# CC2753 register map
File version: 1.0
CPU: CM0+ r0p4, little endian, no MPU, no FPU, VTOR, 3 interrupt priority bits
Registers are 32-bit, read-write, reset 0x0 unless marked. A register's access mark holds for its fields unless they carry their own. Offsets are from the block's base; [hi:lo] are bit positions; {n}, {i} and the like mark numbered series; 'fields as' and 'values as' point back to an identical list.

## LRFDMDM (part 2 of 2)
Base 0x40082000
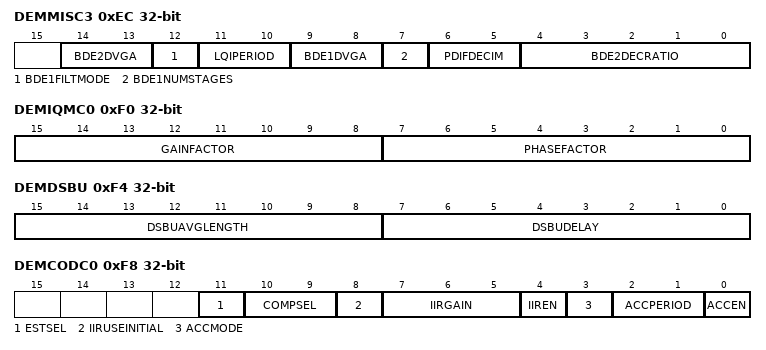
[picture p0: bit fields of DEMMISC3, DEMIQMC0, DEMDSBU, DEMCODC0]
0xEC DEMMISC3 — Internal. Only to be used through TI provided API.
  [14:13] BDE2DVGA — Internal. Only to be used through TI provided API.
    3=GAIN8 (Internal. Only to be used through TI provided API.); 2=GAIN4 (Internal. Only to be used through TI provided API.); 1=GAIN2 (Internal. Only to be used through TI provided API.); 0=GAIN1 (Internal. Only to be used through TI provided API.)
  [12] BDE1FILTMODE — Internal. Only to be used through TI provided API.
    1=DIV2 (Internal. Only to be used through TI provided API.); 0=DIV1 (Internal. Only to be used through TI provided API.)
  [11:10] LQIPERIOD — Internal. Only to be used through TI provided API.
    3=SYM1024 (Internal. Only to be used through TI provided API.); 2=SYM256 (Internal. Only to be used through TI provided API.); 1=SYM64 (Internal. Only to be used through TI provided API.); 0=SYM16 (Internal. Only to be used through TI provided API.)
  [9:8] BDE1DVGA — Internal. Only to be used through TI provided API.
    values as BDE2DVGA
  [7] BDE1NUMSTAGES — Internal. Only to be used through TI provided API.
    values as BDE1FILTMODE
  [6:5] PDIFDECIM — Internal. Only to be used through TI provided API.
    2=DIV4 (Internal. Only to be used through TI provided API.); 1=DIV2 (Internal. Only to be used through TI provided API.); 0=DIV1 (Internal. Only to be used through TI provided API.)
  [4:0] BDE2DECRATIO — Internal. Only to be used through TI provided API.
    3=DIV8 (Internal. Only to be used through TI provided API.); 2=DIV4 (Internal. Only to be used through TI provided API.); 1=DIV2 (Internal. Only to be used through TI provided API.); 0=DIV1 (Internal. Only to be used through TI provided API.)
0xF0 DEMIQMC0 — Internal. Only to be used through TI provided API.
  [15:8] GAINFACTOR — Internal. Only to be used through TI provided API.
    255=ALLONES (Internal. Only to be used through TI provided API.); 0=ALLZEROS (Internal. Only to be used through TI provided API.)
  [7:0] PHASEFACTOR — Internal. Only to be used through TI provided API.
    values as GAINFACTOR
0xF4 DEMDSBU — Internal. Only to be used through TI provided API.
  [15:8] DSBUAVGLENGTH — Internal. Only to be used through TI provided API.
    values as DEMIQMC0.GAINFACTOR
  [7:0] DSBUDELAY — Internal. Only to be used through TI provided API.
    values as DEMIQMC0.GAINFACTOR
0xF8 DEMCODC0 — Internal. Only to be used through TI provided API.
  [11] ESTSEL — Internal. Only to be used through TI provided API.
    1=IIR (Internal. Only to be used through TI provided API.); 0=ACC (Internal. Only to be used through TI provided API.)
  [10:9] COMPSEL — Internal. Only to be used through TI provided API.
    3=IIR (Internal. Only to be used through TI provided API.); 2=ACC (Internal. Only to be used through TI provided API.); 0=MANUAL (Internal. Only to be used through TI provided API.)
  [8] IIRUSEINITIAL — Internal. Only to be used through TI provided API.
    1=EN (Internal. Only to be used through TI provided API.); 0=DIS (Internal. Only to be used through TI provided API.)
  [7:5] IIRGAIN — Internal. Only to be used through TI provided API.
    7=DIV1024 (Internal. Only to be used through TI provided API.); 6=DIV512 (Internal. Only to be used through TI provided API.); 5=DIV256 (Internal. Only to be used through TI provided API.); 4=DIV128 (Internal. Only to be used through TI provided API.); 3=DIV64 (Internal. Only to be used through TI provided API.); 2=DIV32 (Internal. Only to be used through TI provided API.); 1=DIV16 (Internal. Only to be used through TI provided API.); 0=OFF (Internal. Only to be used through TI provided API.)
  [4] IIREN — Internal. Only to be used through TI provided API.
    1=ON (Internal. Only to be used through TI provided API.); 0=OFF (Internal. Only to be used through TI provided API.)
  [3] ACCMODE — Internal. Only to be used through TI provided API.
    1=CONT (Internal. Only to be used through TI provided API.); 0=SINGLE (Internal. Only to be used through TI provided API.)
  [2:1] ACCPERIOD — Internal. Only to be used through TI provided API.
    3=SMPL512 (Internal. Only to be used through TI provided API.); 2=SMPL128 (Internal. Only to be used through TI provided API.); 1=SMPL32 (Internal. Only to be used through TI provided API.); 0=SMPL8 (Internal. Only to be used through TI provided API.)
  [0] ACCEN — Internal. Only to be used through TI provided API.
    values as IIREN
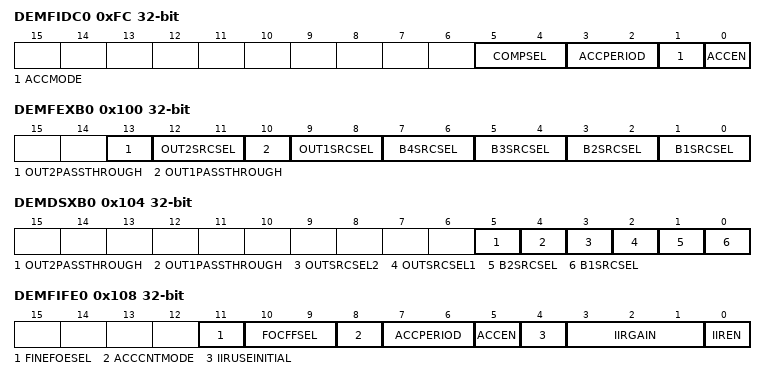
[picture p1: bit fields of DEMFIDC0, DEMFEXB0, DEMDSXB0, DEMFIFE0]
0xFC DEMFIDC0 — Internal. Only to be used through TI provided API.
  [5:4] COMPSEL — Internal. Only to be used through TI provided API.
    2=ACC (Internal. Only to be used through TI provided API.); 0=MANUAL (Internal. Only to be used through TI provided API.)
  [3:2] ACCPERIOD — Internal. Only to be used through TI provided API.
    values as DEMCODC0.ACCPERIOD
  [1] ACCMODE — Internal. Only to be used through TI provided API.
    values as DEMCODC0.ACCMODE
  [0] ACCEN — Internal. Only to be used through TI provided API.
    values as DEMCODC0.IIREN
0x100 DEMFEXB0 — Internal. Only to be used through TI provided API.
  [13] OUT2PASSTHROUGH — Internal. Only to be used through TI provided API.
    1=ONE (Internal. Only to be used through TI provided API.); 0=ZERO (Internal. Only to be used through TI provided API.)
  [12:11] OUT2SRCSEL — Internal. Only to be used through TI provided API.
    2=BDE1 (Internal. Only to be used through TI provided API.); 1=CMIX (Internal. Only to be used through TI provided API.); 0=CODC (Internal. Only to be used through TI provided API.)
  [10] OUT1PASSTHROUGH — Internal. Only to be used through TI provided API.
    values as OUT2PASSTHROUGH
  [9:8] OUT1SRCSEL — Internal. Only to be used through TI provided API.
    values as OUT2SRCSEL
  [7:6] B4SRCSEL — Internal. Only to be used through TI provided API.
    3=ONES (Internal. Only to be used through TI provided API.); 0=ZEROS (Internal. Only to be used through TI provided API.)
  [5:4] B3SRCSEL — Internal. Only to be used through TI provided API.
    2=CMIX (Internal. Only to be used through TI provided API.); 1=CODC (Internal. Only to be used through TI provided API.); 0=INPUT (Internal. Only to be used through TI provided API.)
  [3:2] B2SRCSEL — Internal. Only to be used through TI provided API.
    2=BDE1 (Internal. Only to be used through TI provided API.); 1=CODC (Internal. Only to be used through TI provided API.); 0=INPUT (Internal. Only to be used through TI provided API.)
  [1:0] B1SRCSEL — Internal. Only to be used through TI provided API.
    2=BDE1 (Internal. Only to be used through TI provided API.); 1=CMIX (Internal. Only to be used through TI provided API.); 0=INPUT (Internal. Only to be used through TI provided API.)
0x104 DEMDSXB0 — Internal. Only to be used through TI provided API.
  [5] OUT2PASSTHROUGH — Internal. Only to be used through TI provided API.
    values as DEMFEXB0.OUT2PASSTHROUGH
  [4] OUT1PASSTHROUGH — Internal. Only to be used through TI provided API.
    values as DEMFEXB0.OUT2PASSTHROUGH
  [3] OUTSRCSEL2 — Internal. Only to be used through TI provided API.
    1=MAFI (Internal. Only to be used through TI provided API.); 0=FIFE (Internal. Only to be used through TI provided API.)
  [2] OUTSRCSEL1 — Internal. Only to be used through TI provided API.
    values as OUTSRCSEL2
  [1] B2SRCSEL — Internal. Only to be used through TI provided API.
    1=FIFE (Internal. Only to be used through TI provided API.); 0=INPUT (Internal. Only to be used through TI provided API.)
  [0] B1SRCSEL — Internal. Only to be used through TI provided API.
    1=MAFI (Internal. Only to be used through TI provided API.); 0=INPUT (Internal. Only to be used through TI provided API.)
0x108 DEMFIFE0 — Internal. Only to be used through TI provided API.
  [11] FINEFOESEL — Internal. Only to be used through TI provided API.
    1=ACC (Internal. Only to be used through TI provided API.); 0=IIR (Internal. Only to be used through TI provided API.)
  [10:9] FOCFFSEL — Internal. Only to be used through TI provided API.
    2=MANUAL (Internal. Only to be used through TI provided API.); 1=ACC (Internal. Only to be used through TI provided API.); 0=IIR (Internal. Only to be used through TI provided API.)
  [8] ACCCNTMODE — Internal. Only to be used through TI provided API.
    values as DEMCODC0.ACCMODE
  [7:6] ACCPERIOD — Internal. Only to be used through TI provided API.
    3=PER512 (Internal. Only to be used through TI provided API.); 2=PER256 (Internal. Only to be used through TI provided API.); 1=PER128 (Internal. Only to be used through TI provided API.); 0=PER64 (Internal. Only to be used through TI provided API.)
  [5] ACCEN — Internal. Only to be used through TI provided API.
    values as DEMCODC0.IIREN
  [4] IIRUSEINITIAL — Internal. Only to be used through TI provided API.
    values as DEMCODC0.IIRUSEINITIAL
  [3:1] IIRGAIN — Internal. Only to be used through TI provided API.
    values as DEMCODC0.IIRGAIN
  [0] IIREN — Internal. Only to be used through TI provided API.
    values as DEMCODC0.IIREN
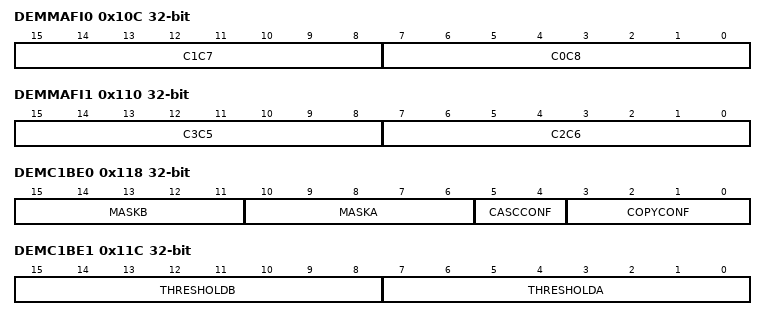
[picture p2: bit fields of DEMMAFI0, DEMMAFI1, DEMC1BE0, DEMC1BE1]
0x10C DEMMAFI0 — Internal. Only to be used through TI provided API.
  [15:8] C1C7 — Internal. Only to be used through TI provided API.
    values as DEMIQMC0.GAINFACTOR
  [7:0] C0C8 — Internal. Only to be used through TI provided API.
    values as DEMIQMC0.GAINFACTOR
0x110 DEMMAFI1 — Internal. Only to be used through TI provided API.
  [15:8] C3C5 — Internal. Only to be used through TI provided API.
    values as DEMIQMC0.GAINFACTOR
  [7:0] C2C6 — Internal. Only to be used through TI provided API.
    values as DEMIQMC0.GAINFACTOR
0x114 DEMMAFI2 — Internal. Only to be used through TI provided API.
  [8:0] C4
    0x1FF=ALLONES (Internal. Only to be used through TI provided API.); 0=ALLZEROS (Internal. Only to be used through TI provided API.)
0x118 DEMC1BE0 — Internal. Only to be used through TI provided API.
  [15:11] MASKB — Internal. Only to be used through TI provided API.
    31=ALLONES (Internal. Only to be used through TI provided API.); 0=ALLZEROS (Internal. Only to be used through TI provided API.)
  [10:6] MASKA — Internal. Only to be used through TI provided API.
    values as MASKB
  [5:4] CASCCONF — Internal. Only to be used through TI provided API.
    2=PARALLEL (Internal. Only to be used through TI provided API.); 1=SERIAL (Internal. Only to be used through TI provided API.); 0=SINGLE (Internal. Only to be used through TI provided API.)
  [3:0] COPYCONF — Internal. Only to be used through TI provided API.
    15=ALLONES (Internal. Only to be used through TI provided API.); 0=ALLZEROS (Internal. Only to be used through TI provided API.)
0x11C DEMC1BE1 — Internal. Only to be used through TI provided API.
  [15:8] THRESHOLDB — Internal. Only to be used through TI provided API.
    values as DEMIQMC0.GAINFACTOR
  [7:0] THRESHOLDA — Internal. Only to be used through TI provided API.
    values as DEMIQMC0.GAINFACTOR
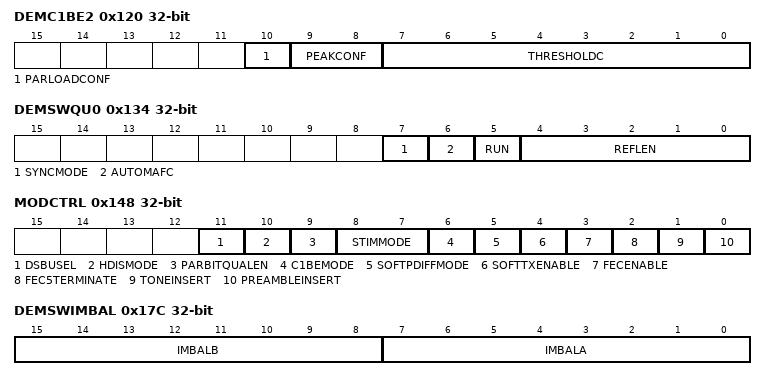
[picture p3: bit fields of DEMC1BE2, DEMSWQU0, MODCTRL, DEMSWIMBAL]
0x120 DEMC1BE2 — Internal. Only to be used through TI provided API.
  [10] PARLOADCONF — Internal. Only to be used through TI provided API.
    1=ATOD (Internal. Only to be used through TI provided API.); 0=ATOB (Internal. Only to be used through TI provided API.)
  [9:8] PEAKCONF — Internal. Only to be used through TI provided API.
    2=BESTAB (Internal. Only to be used through TI provided API.); 1=BEST (Internal. Only to be used through TI provided API.); 0=THRESH (Internal. Only to be used through TI provided API.)
  [7:0] THRESHOLDC — Internal. Only to be used through TI provided API.
    values as DEMIQMC0.GAINFACTOR
{0x124+4i} SPARE{i} (i=0..3) — Internal. Only to be used through TI provided API.
  [15:0] VAL
    0xFFFF=ALLONES (Internal. Only to be used through TI provided API.); 0=ALLZEROS (Internal. Only to be used through TI provided API.)
0x134 DEMSWQU0 — Internal. Only to be used through TI provided API.
  [7] SYNCMODE — Internal. Only to be used through TI provided API.
    values as DEMFEXB0.OUT2PASSTHROUGH
  [6] AUTOMAFC — Internal. Only to be used through TI provided API.
    values as DEMCODC0.IIREN
  [5] RUN — Internal. Only to be used through TI provided API.
    values as DEMCODC0.IIREN
  [4:0] REFLEN — Internal. Only to be used through TI provided API.
    values as DEMC1BE0.MASKB
0x138 DEMC1BEREF0 — Internal. Only to be used through TI provided API.
  [15:0] CAR15C0
    values as SPARE0.VAL
0x13C DEMC1BEREF1 — Internal. Only to be used through TI provided API.
  [15:0] CAR31C16
    values as SPARE0.VAL
0x140 DEMC1BEREF2 — Internal. Only to be used through TI provided API.
  [15:0] CBR15C0
    values as SPARE0.VAL
0x144 DEMC1BEREF3 — Internal. Only to be used through TI provided API.
  [15:0] CBR31C16
    values as SPARE0.VAL
0x148 MODCTRL — Internal. Only to be used through TI provided API.
  [11] DSBUSEL — Internal. Only to be used through TI provided API.
    values as DEMFEXB0.OUT2PASSTHROUGH
  [10] HDISMODE — Internal. Only to be used through TI provided API.
    values as DEMCODC0.IIRUSEINITIAL
  [9] PARBITQUALEN — Internal. Only to be used through TI provided API.
    values as DEMCODC0.IIREN
  [8:7] STIMMODE — Internal. Only to be used through TI provided API.
    2=EARLY (Internal. Only to be used through TI provided API.); 1=LATE (Internal. Only to be used through TI provided API.); 0=NORMAL (Internal. Only to be used through TI provided API.)
  [6] C1BEMODE — Internal. Only to be used through TI provided API.
    1=EARLYLATE (Internal. Only to be used through TI provided API.); 0=NORMAL (Internal. Only to be used through TI provided API.)
  [5] SOFTPDIFFMODE — Internal. Only to be used through TI provided API.
    values as DEMCODC0.IIRUSEINITIAL
  [4] SOFTTXENABLE — Internal. Only to be used through TI provided API.
    values as DEMCODC0.IIREN
  [3] FECENABLE — Internal. Only to be used through TI provided API.
    values as DEMCODC0.IIREN
  [2] FEC5TERMINATE — Internal. Only to be used through TI provided API.
    values as DEMCODC0.IIREN
  [1] TONEINSERT — Internal. Only to be used through TI provided API.
    values as DEMCODC0.IIRUSEINITIAL
  [0] PREAMBLEINSERT — Internal. Only to be used through TI provided API.
    values as DEMCODC0.IIRUSEINITIAL
0x14C MODPREAMBLE — Internal. Only to be used through TI provided API.
  [15:0] WORD
    values as SPARE0.VAL
0x150 DEMFRAC0 — Internal. Only to be used through TI provided API.
  [15:0] P15C0
    values as SPARE0.VAL
0x154 DEMFRAC1 — Internal. Only to be used through TI provided API.
  [11:0] P27C16
    0xFFF=ALLONES (Internal. Only to be used through TI provided API.); 0=ALLZEROS (Internal. Only to be used through TI provided API.)
0x158 DEMFRAC2 — Internal. Only to be used through TI provided API.
  [15:0] Q15C0
    values as SPARE0.VAL
0x15C DEMFRAC3 — Internal. Only to be used through TI provided API.
  [11:0] Q27C16
    values as DEMFRAC1.P27C16
0x160 DEMCODC1 — Internal. Only to be used through TI provided API.
  [12:0] COMPIVAL
    0x1FFF=ALLONES (Internal. Only to be used through TI provided API.); 0=ALLZEROS (Internal. Only to be used through TI provided API.)
0x164 DEMCODC2 — Internal. Only to be used through TI provided API.
  [12:0] COMPQVAL
    values as DEMCODC1.COMPIVAL
0x168 DEMFIDC1 — Internal. Only to be used through TI provided API.
  fields as DEMCODC1
0x16C DEMFIDC2 — Internal. Only to be used through TI provided API.
  fields as DEMCODC2
0x170 DEMFIFE1 — Internal. Only to be used through TI provided API.
  [7:0] FOCFBREGVAL
    values as DEMIQMC0.GAINFACTOR
0x174 DEMMAFC0 — Internal. Only to be used through TI provided API.
  [7:0] COMPVAL
    values as DEMIQMC0.GAINFACTOR
0x178 DEMMAFI4 — Internal. Only to be used through TI provided API.
  [7:0] TERMVAL
    values as DEMIQMC0.GAINFACTOR
0x17C DEMSWIMBAL — Internal. Only to be used through TI provided API.
  [15:8] IMBALB — Internal. Only to be used through TI provided API.
    values as DEMIQMC0.GAINFACTOR
  [7:0] IMBALA — Internal. Only to be used through TI provided API.
    values as DEMIQMC0.GAINFACTOR
0x180 DEMSOFTPDIFF — Internal. Only to be used through TI provided API.
  [7:0] VAL
    values as DEMIQMC0.GAINFACTOR
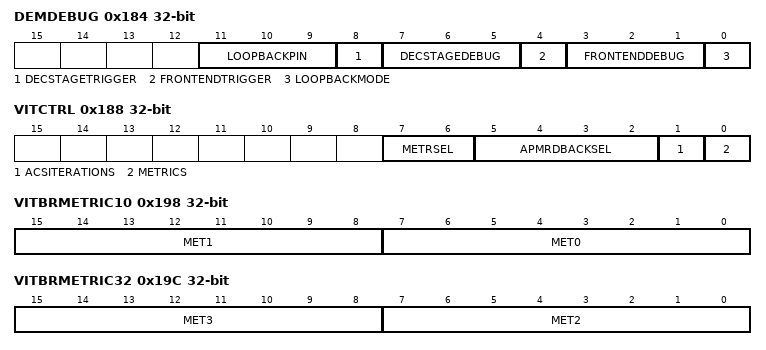
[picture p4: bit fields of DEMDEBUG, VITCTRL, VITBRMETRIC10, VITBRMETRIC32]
0x184 DEMDEBUG — Internal. Only to be used through TI provided API.
  [11:9] LOOPBACKPIN — Internal. Only to be used through TI provided API.
    {v}=GPI{v} (Internal. Only to be used through TI provided API.) (v=0..7)
  [8] DECSTAGETRIGGER — Internal. Only to be used through TI provided API.
    values as DEMFEXB0.OUT2PASSTHROUGH
  [7:5] DECSTAGEDEBUG — Internal. Only to be used through TI provided API.
    7=SOFD (Internal. Only to be used through TI provided API.); 6=STIM (Internal. Only to be used through TI provided API.); 5=MAFC (Internal. Only to be used through TI provided API.); 4=C1BE (Internal. Only to be used through TI provided API.); 3=MAFI (Internal. Only to be used through TI provided API.); 2=FIFE (Internal. Only to be used through TI provided API.); 1=PDIF (Internal. Only to be used through TI provided API.); 0=NOSEL (Internal. Only to be used through TI provided API.)
  [4] FRONTENDTRIGGER — Internal. Only to be used through TI provided API.
    values as DEMFEXB0.OUT2PASSTHROUGH
  [3:1] FRONTENDDEBUG — Internal. Only to be used through TI provided API.
    7=FIDC (Internal. Only to be used through TI provided API.); 6=FRAC (Internal. Only to be used through TI provided API.); 5=CHFI (Internal. Only to be used through TI provided API.); 4=BDE2 (Internal. Only to be used through TI provided API.); 3=FEXB2 (Internal. Only to be used through TI provided API.); 2=BDE1 (Internal. Only to be used through TI provided API.); 1=IQMC (Internal. Only to be used through TI provided API.); 0=NOSEL (Internal. Only to be used through TI provided API.)
  [0] LOOPBACKMODE — Internal. Only to be used through TI provided API.
    values as DEMFEXB0.OUT2PASSTHROUGH
0x188 VITCTRL — Internal. Only to be used through TI provided API.
  [7:6] METRSEL — Internal. Only to be used through TI provided API.
    3=MLSE (Internal. Only to be used through TI provided API.); 2=SOFD (Internal. Only to be used through TI provided API.); 1=PHAC (Internal. Only to be used through TI provided API.); 0=MET5M (Internal. Only to be used through TI provided API.)
  [5:2] APMRDBACKSEL — Internal. Only to be used through TI provided API.
    {v}=APM{v-8} (Internal. Only to be used through TI provided API.) (v=8..15); 0=NOSEL (Internal. Only to be used through TI provided API.)
  [1] ACSITERATIONS — Internal. Only to be used through TI provided API.
    1=CODE23 (Internal. Only to be used through TI provided API.); 0=CODE12 (Internal. Only to be used through TI provided API.)
  [0] METRICS — Internal. Only to be used through TI provided API.
    1=SOFT (Internal. Only to be used through TI provided API.); 0=HW (Internal. Only to be used through TI provided API.)
0x18C VITCOMPUTE wo — Internal. Only to be used through TI provided API.
  [0] START
    values as DEMFEXB0.OUT2PASSTHROUGH
0x190 VITAPMRDBACK ro — Internal. Only to be used through TI provided API.
  [9:0] VALUE
    0x3FF=ALLONES (Internal. Only to be used through TI provided API.); 0=ALLZEROS (Internal. Only to be used through TI provided API.)
0x194 VITSTATE ro — Internal. Only to be used through TI provided API.
  [2:0] VALUE
    7=ALLONES (Internal. Only to be used through TI provided API.); 0=ALLZEROS (Internal. Only to be used through TI provided API.)
0x198 VITBRMETRIC10 — Internal. Only to be used through TI provided API.
  [15:8] MET1 — Internal. Only to be used through TI provided API.
    values as DEMIQMC0.GAINFACTOR
  [7:0] MET0 — Internal. Only to be used through TI provided API.
    values as DEMIQMC0.GAINFACTOR
0x19C VITBRMETRIC32 — Internal. Only to be used through TI provided API.
  [15:8] MET3 — Internal. Only to be used through TI provided API.
    values as DEMIQMC0.GAINFACTOR
  [7:0] MET2 — Internal. Only to be used through TI provided API.
    values as DEMIQMC0.GAINFACTOR
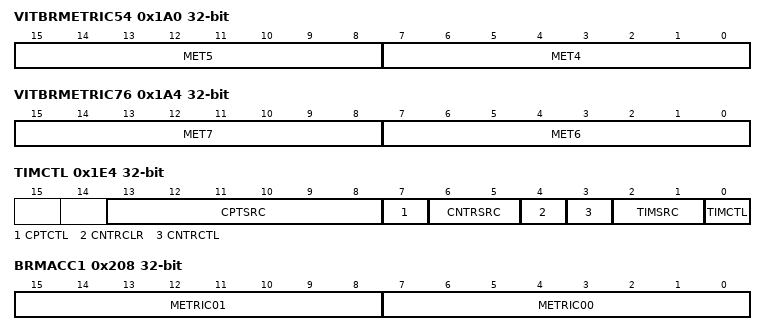
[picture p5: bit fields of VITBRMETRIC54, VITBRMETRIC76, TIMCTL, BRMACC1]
0x1A0 VITBRMETRIC54 — Internal. Only to be used through TI provided API.
  [15:8] MET5 — Internal. Only to be used through TI provided API.
    values as DEMIQMC0.GAINFACTOR
  [7:0] MET4 — Internal. Only to be used through TI provided API.
    values as DEMIQMC0.GAINFACTOR
0x1A4 VITBRMETRIC76 — Internal. Only to be used through TI provided API.
  [15:8] MET7 — Internal. Only to be used through TI provided API.
    values as DEMIQMC0.GAINFACTOR
  [7:0] MET6 — Internal. Only to be used through TI provided API.
    values as DEMIQMC0.GAINFACTOR
0x1E4 TIMCTL — Internal. Only to be used through TI provided API.
  [13:8] CPTSRC — Internal. Only to be used through TI provided API.
    63=ALLONES (Internal. Only to be used through TI provided API.); 0=ALLZEROS (Internal. Only to be used through TI provided API.)
  [7] CPTCTL — Internal. Only to be used through TI provided API.
    values as DEMCODC0.IIRUSEINITIAL
  [6:5] CNTRSRC — Internal. Only to be used through TI provided API.
    3=CLK4BAUDF (Internal. Only to be used through TI provided API.); 2=CLK4BAUD (Internal. Only to be used through TI provided API.); 1=CLKBAUD (Internal. Only to be used through TI provided API.); 0=CLK (Internal. Only to be used through TI provided API.)
  [4] CNTRCLR — Internal. Only to be used through TI provided API.
    values as DEMFEXB0.OUT2PASSTHROUGH
  [3] CNTRCTL — Internal. Only to be used through TI provided API.
    values as DEMFEXB0.OUT2PASSTHROUGH
  [2:1] TIMSRC — Internal. Only to be used through TI provided API.
    values as CNTRSRC
  [0] TIMCTL — Internal. Only to be used through TI provided API.
    values as DEMCODC0.IIRUSEINITIAL
0x1E8 TIMINC — Internal. Only to be used through TI provided API.
  fields as SPARE0
0x1EC TIMPER — Internal. Only to be used through TI provided API.
  fields as SPARE0
0x1F0 TIMCNT ro — Internal. Only to be used through TI provided API.
  fields as SPARE0
0x1F4 TIMCAPT ro — Internal. Only to be used through TI provided API.
  [15:0] VALUE
    values as SPARE0.VAL
0x1F8 TIMEBASE wo — Internal. Only to be used through TI provided API.
  [0] FLUSH
    values as DEMFEXB0.OUT2PASSTHROUGH
0x1FC COUNT1IN — Internal. Only to be used through TI provided API.
  fields as SPARE0
0x200 COUNT1RES ro — Internal. Only to be used through TI provided API.
  [4:0] VAL
    values as DEMC1BE0.MASKB
0x208 BRMACC1 ro — Internal. Only to be used through TI provided API.
  [15:8] METRIC01 — Internal. Only to be used through TI provided API.
    values as DEMIQMC0.GAINFACTOR
  [7:0] METRIC00 — Internal. Only to be used through TI provided API.
    values as DEMIQMC0.GAINFACTOR
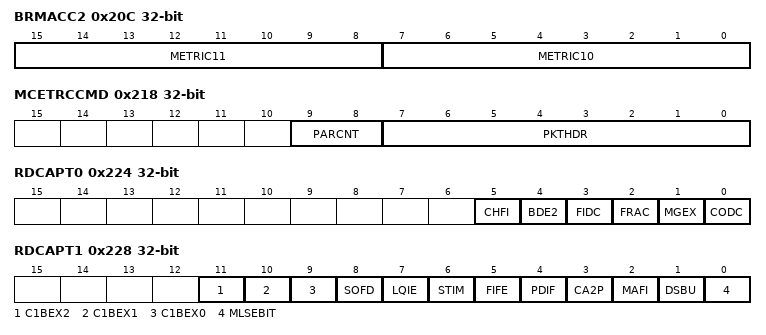
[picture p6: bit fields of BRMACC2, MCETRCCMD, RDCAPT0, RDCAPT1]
0x20C BRMACC2 ro — Internal. Only to be used through TI provided API.
  [15:8] METRIC11 — Internal. Only to be used through TI provided API.
    values as DEMIQMC0.GAINFACTOR
  [7:0] METRIC10 — Internal. Only to be used through TI provided API.
    values as DEMIQMC0.GAINFACTOR
0x210 MCETRCCTRL wo — Internal. Only to be used through TI provided API.
  [0] SEND
    values as DEMFEXB0.OUT2PASSTHROUGH
0x214 MCETRCSTAT ro — Internal. Only to be used through TI provided API.
  [0] BUSY
    values as DEMFEXB0.OUT2PASSTHROUGH
0x218 MCETRCCMD — Internal. Only to be used through TI provided API.
  [9:8] PARCNT — Internal. Only to be used through TI provided API.
    3=ALLONES (Internal. Only to be used through TI provided API.); 0=ALLZEROS (Internal. Only to be used through TI provided API.)
  [7:0] PKTHDR — Internal. Only to be used through TI provided API.
    values as DEMIQMC0.GAINFACTOR
0x21C MCETRCPAR0 — Internal. Only to be used through TI provided API.
  fields as SPARE0
0x220 MCETRCPAR1 — Internal. Only to be used through TI provided API.
  fields as SPARE0
0x224 RDCAPT0 wo — Internal. Only to be used through TI provided API.
  [all] fields
    values as DEMFEXB0.OUT2PASSTHROUGH
  [5] CHFI — Internal. Only to be used through TI provided API.
  [4] BDE2 — Internal. Only to be used through TI provided API.
  [3] FIDC — Internal. Only to be used through TI provided API.
  [2] FRAC — Internal. Only to be used through TI provided API.
  [1] MGEX — Internal. Only to be used through TI provided API.
  [0] CODC — Internal. Only to be used through TI provided API.
0x228 RDCAPT1 wo — Internal. Only to be used through TI provided API.
  [all] fields
    values as DEMFEXB0.OUT2PASSTHROUGH
  [11] C1BEX2 — Internal. Only to be used through TI provided API.
  [10] C1BEX1 — Internal. Only to be used through TI provided API.
  [9] C1BEX0 — Internal. Only to be used through TI provided API.
  [8] SOFD — Internal. Only to be used through TI provided API.
  [7] LQIE — Internal. Only to be used through TI provided API.
  [6] STIM — Internal. Only to be used through TI provided API.
  [5] FIFE — Internal. Only to be used through TI provided API.
  [4] PDIF — Internal. Only to be used through TI provided API.
  [3] CA2P — Internal. Only to be used through TI provided API.
  [2] MAFI — Internal. Only to be used through TI provided API.
  [1] DSBU — Internal. Only to be used through TI provided API.
  [0] MLSEBIT — Internal. Only to be used through TI provided API.
0x22C FECAPT0 — Internal. Only to be used through TI provided API.
  [12:0] VAL
    values as DEMCODC1.COMPIVAL
0x230 FECAPT1 — Internal. Only to be used through TI provided API.
  fields as FECAPT0
{0x234+4i} DSCAPT{i} (i=0..3) — Internal. Only to be used through TI provided API.
  fields as DEMSOFTPDIFF
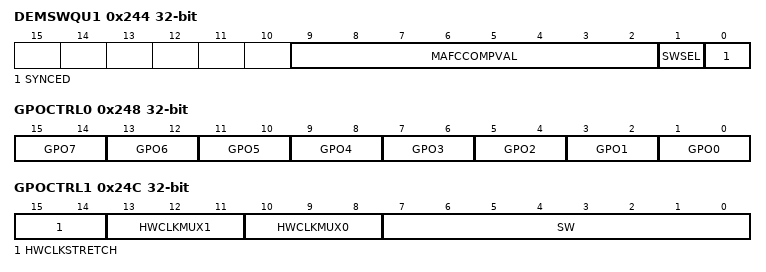
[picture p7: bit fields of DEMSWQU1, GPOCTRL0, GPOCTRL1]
0x244 DEMSWQU1 — Internal. Only to be used through TI provided API.
  [9:2] MAFCCOMPVAL ro — Internal. Only to be used through TI provided API.
    values as DEMIQMC0.GAINFACTOR
  [1] SWSEL ro — Internal. Only to be used through TI provided API.
    1=B (Internal. Only to be used through TI provided API.); 0=A (Internal. Only to be used through TI provided API.)
  [0] SYNCED ro — Internal. Only to be used through TI provided API.
    values as DEMFEXB0.OUT2PASSTHROUGH
0x248 GPOCTRL0 — Internal. Only to be used through TI provided API.
  [15:14] GPO7 — Internal. Only to be used through TI provided API.
    3=THREE (Internal. Only to be used through TI provided API.); 2=TWO (Internal. Only to be used through TI provided API.); 1=TOPSM_WAIT (Internal. Only to be used through TI provided API.); 0=SW7 (Internal. Only to be used through TI provided API.)
  [13:12] GPO6 — Internal. Only to be used through TI provided API.
    3=THREE (Internal. Only to be used through TI provided API.); 2=TWO (Internal. Only to be used through TI provided API.); 1=TRANSPARENT_OUT (Internal. Only to be used through TI provided API.); 0=SW6 (Internal. Only to be used through TI provided API.)
  [11:10] GPO5 — Internal. Only to be used through TI provided API.
    3=THREE (Internal. Only to be used through TI provided API.); 2=TWO (Internal. Only to be used through TI provided API.); 1=DEM_OUT_WORD (Internal. Only to be used through TI provided API.); 0=SW5 (Internal. Only to be used through TI provided API.)
  [9:8] GPO4 — Internal. Only to be used through TI provided API.
    3=THREE (Internal. Only to be used through TI provided API.); 2=TWO (Internal. Only to be used through TI provided API.); 1=CORR_PEAK_C (Internal. Only to be used through TI provided API.); 0=SW4 (Internal. Only to be used through TI provided API.)
  [7:6] GPO3 — Internal. Only to be used through TI provided API.
    3=THREE (Internal. Only to be used through TI provided API.); 2=TWO (Internal. Only to be used through TI provided API.); 1=CORR_PEAK_B (Internal. Only to be used through TI provided API.); 0=SW3 (Internal. Only to be used through TI provided API.)
  [5:4] GPO2 — Internal. Only to be used through TI provided API.
    3=THREE (Internal. Only to be used through TI provided API.); 2=TWO (Internal. Only to be used through TI provided API.); 1=CORR_PEAK_A (Internal. Only to be used through TI provided API.); 0=SW2 (Internal. Only to be used through TI provided API.)
  [3:2] GPO1 — Internal. Only to be used through TI provided API.
    3=THREE (Internal. Only to be used through TI provided API.); 2=TWO (Internal. Only to be used through TI provided API.); 1=HWCLK1 (Internal. Only to be used through TI provided API.); 0=SW1 (Internal. Only to be used through TI provided API.)
  [1:0] GPO0 — Internal. Only to be used through TI provided API.
    3=THREE (Internal. Only to be used through TI provided API.); 2=LOOPBACK (Internal. Only to be used through TI provided API.); 1=HWCLK0 (Internal. Only to be used through TI provided API.); 0=SW0 (Internal. Only to be used through TI provided API.)
0x24C GPOCTRL1 — Internal. Only to be used through TI provided API.
  [all] fields
    values as DEMFEXB0.OUT2PASSTHROUGH
  [15:14] HWCLKSTRETCH — Internal. Only to be used through TI provided API.
  [13:11] HWCLKMUX1 — Internal. Only to be used through TI provided API.
  [10:8] HWCLKMUX0 — Internal. Only to be used through TI provided API.
  [7:0] SW — Internal. Only to be used through TI provided API.
0x250 RFERSSI ro — Internal. Only to be used through TI provided API.
  fields as DEMSOFTPDIFF
0x254 RFEMAXRSSI ro — Internal. Only to be used through TI provided API.
  fields as DEMSOFTPDIFF
0x258 RFEDBGAIN ro — Internal. Only to be used through TI provided API.
  fields as DEMSOFTPDIFF
0x25C SYNC0 ro — Internal. Only to be used through TI provided API.
  [15:0] SWA15C0
    values as SPARE0.VAL
0x260 SYNC1 ro — Internal. Only to be used through TI provided API.
  [15:0] SWA31C16
    values as SPARE0.VAL
0x264 SYNC2 ro — Internal. Only to be used through TI provided API.
  [15:0] SWB15C0
    values as SPARE0.VAL
0x268 SYNC3 ro — Internal. Only to be used through TI provided API.
  [15:0] SWB31C16
    values as SPARE0.VAL
